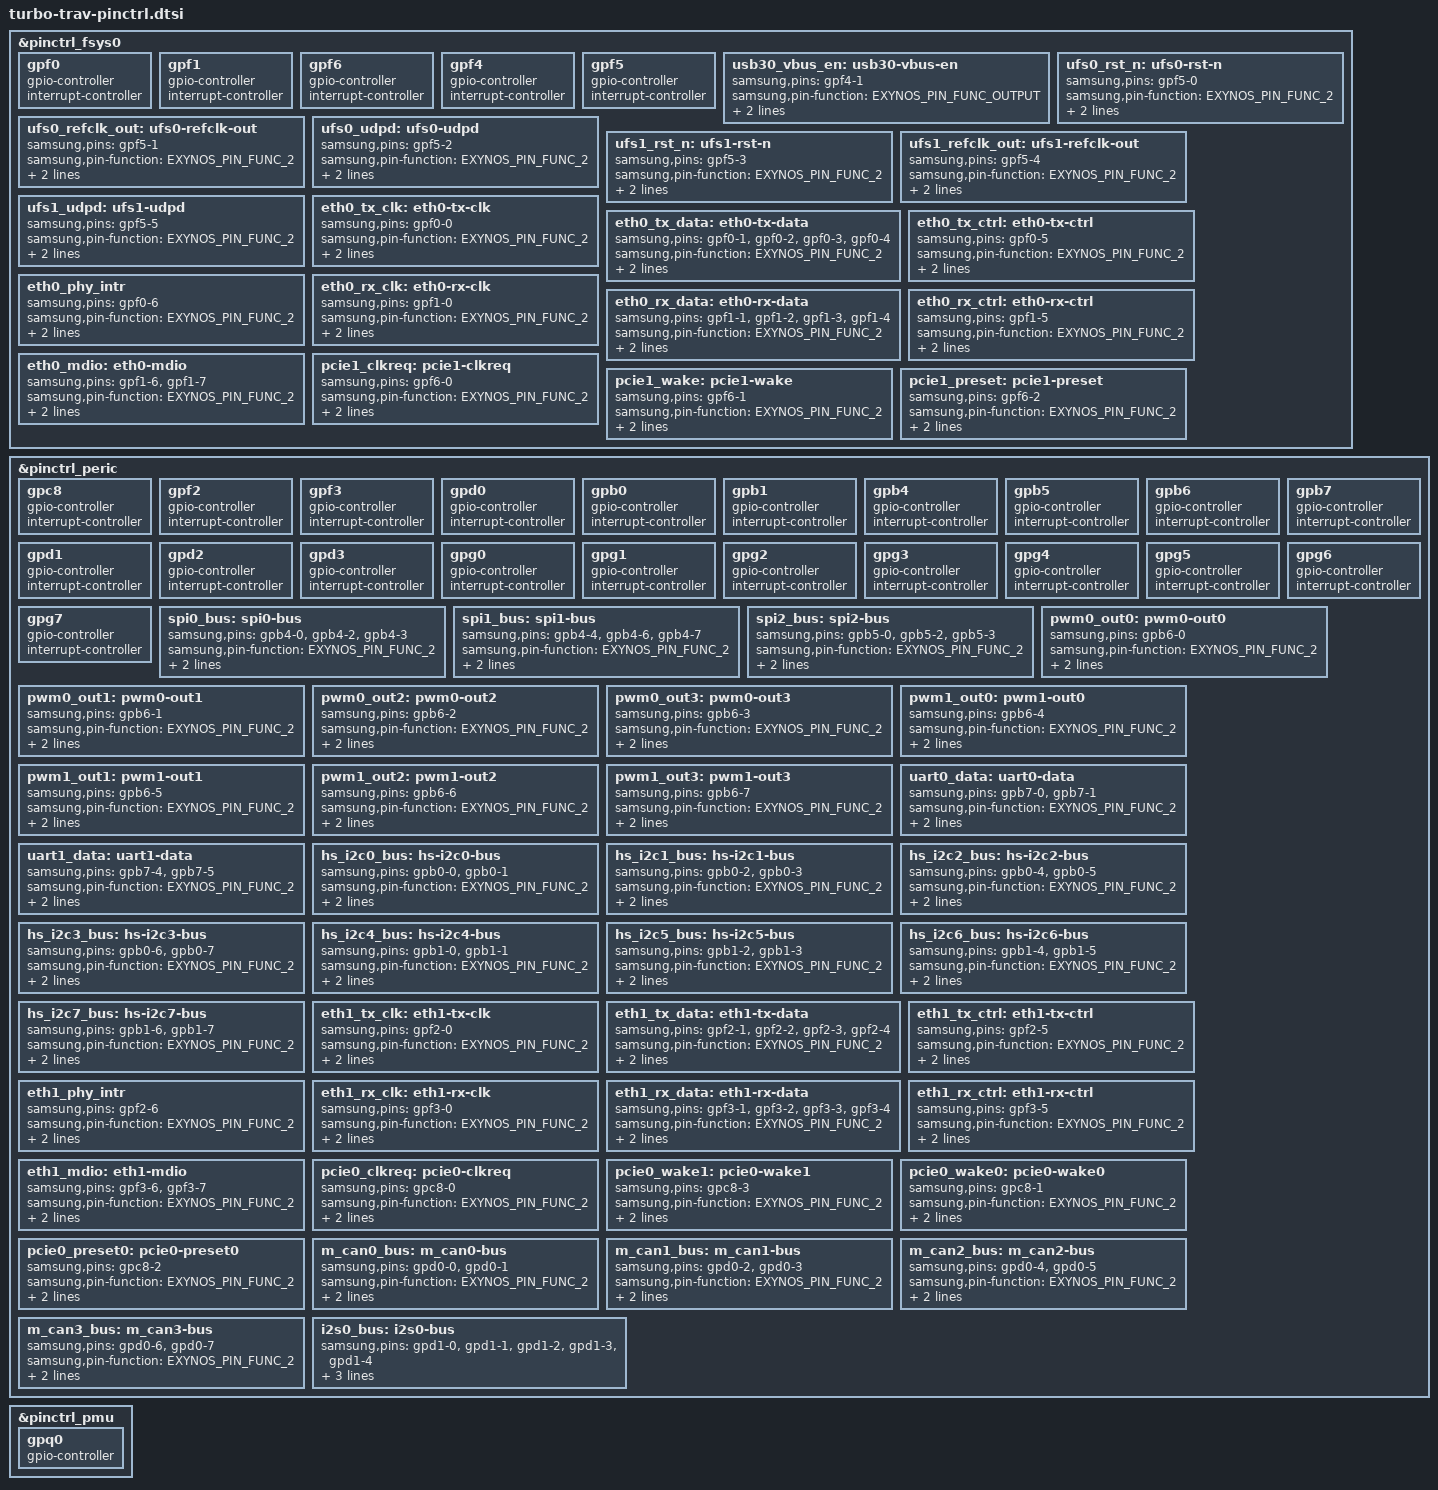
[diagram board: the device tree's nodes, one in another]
/*
 * Samsung's TRAV SoC pin-mux and pin-config device tree source
 *
 * Copyright (c) 2017 Samsung Electronics Co., Ltd.
 *		http://www.samsung.com
 *
 * Samsung's TRAV SoC pin-mux and pin-config options are listed as device
 * tree nodes are listed in this file.
 *
 * This program is free software; you can redistribute it and/or modify
 * it under the terms of the GNU General Public License version 2 as
 * published by the Free Software Foundation.
 */

#include <dt-bindings/pinctrl/samsung.h>

&pinctrl_fsys0 {

	gpf0 {
		gpio-controller;
		#gpio-cells = <2>;

		interrupt-controller;
		#interrupt-cells = <2>;
	};

	gpf1 {
		gpio-controller;
		#gpio-cells = <2>;

		interrupt-controller;
		#interrupt-cells = <2>;
	};

	gpf6: gpf6 {
		gpio-controller;
		#gpio-cells = <2>;

		interrupt-controller;
		#interrupt-cells = <2>;
	};

	gpf4: gpf4 {
		gpio-controller;
		#gpio-cells = <2>;

		interrupt-controller;
		#interrupt-cells = <2>;
	};

	gpf5 {
		gpio-controller;
		#gpio-cells = <2>;

		interrupt-controller;
		#interrupt-cells = <2>;
	};

	usb30_vbus_en: usb30-vbus-en {
		samsung,pins = "gpf4-1";
		samsung,pin-function = <EXYNOS_PIN_FUNC_OUTPUT>;
		samsung,pin-pud = <EXYNOS_PIN_PULL_NONE>;
		samsung,pin-drv = <EXYNOS4_PIN_DRV_LV2>;
	};

	ufs0_rst_n: ufs0-rst-n {
		samsung,pins = "gpf5-0";
		samsung,pin-function = <EXYNOS_PIN_FUNC_2>;
		samsung,pin-pud = <EXYNOS_PIN_PULL_NONE>;
		samsung,pin-drv = <EXYNOS4_PIN_DRV_LV2>;
	};

	ufs0_refclk_out: ufs0-refclk-out {
		samsung,pins = "gpf5-1";
		samsung,pin-function = <EXYNOS_PIN_FUNC_2>;
		samsung,pin-pud = <EXYNOS_PIN_PULL_NONE>;
		samsung,pin-drv = <EXYNOS4_PIN_DRV_LV2>;
	};

	ufs0_udpd: ufs0-udpd {
		samsung,pins = "gpf5-2";
		samsung,pin-function = <EXYNOS_PIN_FUNC_2>;
		samsung,pin-pud = <EXYNOS_PIN_PULL_NONE>;
		samsung,pin-drv = <EXYNOS4_PIN_DRV_LV2>;
	};

	ufs1_rst_n: ufs1-rst-n {
		samsung,pins = "gpf5-3";
		samsung,pin-function = <EXYNOS_PIN_FUNC_2>;
		samsung,pin-pud = <EXYNOS_PIN_PULL_NONE>;
		samsung,pin-drv = <EXYNOS4_PIN_DRV_LV2>;
	};

	ufs1_refclk_out: ufs1-refclk-out {
		samsung,pins = "gpf5-4";
		samsung,pin-function = <EXYNOS_PIN_FUNC_2>;
		samsung,pin-pud = <EXYNOS_PIN_PULL_NONE>;
		samsung,pin-drv = <EXYNOS4_PIN_DRV_LV2>;
	};

	ufs1_udpd: ufs1-udpd {
		samsung,pins = "gpf5-5";
		samsung,pin-function = <EXYNOS_PIN_FUNC_2>;
		samsung,pin-pud = <EXYNOS_PIN_PULL_NONE>;
		samsung,pin-drv = <EXYNOS4_PIN_DRV_LV2>;
	};

	eth0_tx_clk: eth0-tx-clk {
		samsung,pins = "gpf0-0";
		samsung,pin-function = <EXYNOS_PIN_FUNC_2>;
		samsung,pin-pud = <EXYNOS_PIN_PULL_DOWN>;
		samsung,pin-drv = <EXYNOS4_PIN_DRV_LV4>;
	};

	eth0_tx_data: eth0-tx-data {
		samsung,pins = "gpf0-1", "gpf0-2", "gpf0-3", "gpf0-4";
		samsung,pin-function = <EXYNOS_PIN_FUNC_2>;
		samsung,pin-pud = <EXYNOS_PIN_PULL_UP>;
		samsung,pin-drv = <EXYNOS4_PIN_DRV_LV4>;
	};

	eth0_tx_ctrl: eth0-tx-ctrl {
		samsung,pins = "gpf0-5";
		samsung,pin-function = <EXYNOS_PIN_FUNC_2>;
		samsung,pin-pud = <EXYNOS_PIN_PULL_UP>;
		samsung,pin-drv = <EXYNOS4_PIN_DRV_LV4>;
	};

	eth0_phy_intr: eth0_phy_intr {
		samsung,pins = "gpf0-6";
		samsung,pin-function = <EXYNOS_PIN_FUNC_2>;
		samsung,pin-pud = <EXYNOS_PIN_PULL_NONE>;
		samsung,pin-drv = <EXYNOS4_PIN_DRV_LV2>;
	};

	eth0_rx_clk: eth0-rx-clk {
		samsung,pins = "gpf1-0";
		samsung,pin-function = <EXYNOS_PIN_FUNC_2>;
		samsung,pin-pud = <EXYNOS_PIN_PULL_UP>;
		samsung,pin-drv = <EXYNOS4_PIN_DRV_LV4>;
	};

	eth0_rx_data: eth0-rx-data {
		samsung,pins = "gpf1-1", "gpf1-2", "gpf1-3", "gpf1-4";
		samsung,pin-function = <EXYNOS_PIN_FUNC_2>;
		samsung,pin-pud = <EXYNOS_PIN_PULL_UP>;
		samsung,pin-drv = <EXYNOS4_PIN_DRV_LV4>;
	};

	eth0_rx_ctrl: eth0-rx-ctrl {
		samsung,pins = "gpf1-5";
		samsung,pin-function = <EXYNOS_PIN_FUNC_2>;
		samsung,pin-pud = <EXYNOS_PIN_PULL_UP>;
		samsung,pin-drv = <EXYNOS4_PIN_DRV_LV4>;
	};

	eth0_mdio: eth0-mdio {
		samsung,pins = "gpf1-6", "gpf1-7";
		samsung,pin-function = <EXYNOS_PIN_FUNC_2>;
		samsung,pin-pud = <EXYNOS_PIN_PULL_NONE>;
		samsung,pin-drv = <EXYNOS4_PIN_DRV_LV2>;
	};

	pcie1_clkreq: pcie1-clkreq {
		samsung,pins = "gpf6-0";
		samsung,pin-function = <EXYNOS_PIN_FUNC_2>;
		samsung,pin-pud = <EXYNOS_PIN_PULL_UP>;
		samsung,pin-drv = <EXYNOS4_PIN_DRV_LV2>;
	};

	pcie1_wake: pcie1-wake {
		samsung,pins = "gpf6-1";
		samsung,pin-function = <EXYNOS_PIN_FUNC_2>;
		samsung,pin-pud = <EXYNOS_PIN_PULL_UP>;
		samsung,pin-drv = <EXYNOS4_PIN_DRV_LV2>;
	};

	pcie1_preset: pcie1-preset {
		samsung,pins = "gpf6-2";
		samsung,pin-function = <EXYNOS_PIN_FUNC_2>;
		samsung,pin-pud = <EXYNOS_PIN_PULL_UP>;
		samsung,pin-drv = <EXYNOS4_PIN_DRV_LV2>;
	};
};

&pinctrl_peric {

	gpc8: gpc8 {
		gpio-controller;
		#gpio-cells = <2>;

		interrupt-controller;
		#interrupt-cells = <2>;
	};

	gpf2: gpf2 {
		gpio-controller;
		#gpio-cells = <2>;

		interrupt-controller;
		#interrupt-cells = <2>;
	};

	gpf3: gpf3 {
		gpio-controller;
		#gpio-cells = <2>;

		interrupt-controller;
		#interrupt-cells = <2>;
	};

	gpd0: gpd0 {
		gpio-controller;
		#gpio-cells = <2>;

		interrupt-controller;
		#interrupt-cells = <2>;
	};

	gpb0: gpb0 {
		gpio-controller;
		#gpio-cells = <2>;

		interrupt-controller;
		#interrupt-cells = <2>;
	};

	gpb1: gpb1 {
		gpio-controller;
		#gpio-cells = <2>;

		interrupt-controller;
		#interrupt-cells = <2>;
	};

	gpb4: gpb4 {
		gpio-controller;
		#gpio-cells = <2>;

		interrupt-controller;
		#interrupt-cells = <2>;
	};

	gpb5: gpb5 {
		gpio-controller;
		#gpio-cells = <2>;

		interrupt-controller;
		#interrupt-cells = <2>;
	};

	gpb6: gpb6 {
		gpio-controller;
		#gpio-cells = <2>;

		interrupt-controller;
		#interrupt-cells = <2>;
	};

	gpb7: gpb7 {
		gpio-controller;
		#gpio-cells = <2>;

		interrupt-controller;
		#interrupt-cells = <2>;
	};

	gpd1: gpd1 {
		gpio-controller;
		#gpio-cells = <2>;

		interrupt-controller;
		#interrupt-cells = <2>;
	};

	gpd2: gpd2 {
		gpio-controller;
		#gpio-cells = <2>;

		interrupt-controller;
		#interrupt-cells = <2>;
	};

	gpd3: gpd3 {
		gpio-controller;
		#gpio-cells = <2>;

		interrupt-controller;
		#interrupt-cells = <2>;
	};

	gpg0: gpg0 {
		gpio-controller;
		#gpio-cells = <2>;

		interrupt-controller;
		#interrupt-cells = <2>;
	};

	gpg1: gpg1 {
		gpio-controller;
		#gpio-cells = <2>;

		interrupt-controller;
		#interrupt-cells = <2>;
	};

	gpg2: gpg2 {
		gpio-controller;
		#gpio-cells = <2>;

		interrupt-controller;
		#interrupt-cells = <2>;
	};

	gpg3: gpg3 {
		gpio-controller;
		#gpio-cells = <2>;

		interrupt-controller;
		#interrupt-cells = <2>;
	};

	gpg4: gpg4 {
		gpio-controller;
		#gpio-cells = <2>;

		interrupt-controller;
		#interrupt-cells = <2>;
	};

	gpg5: gpg5 {
		gpio-controller;
		#gpio-cells = <2>;

		interrupt-controller;
		#interrupt-cells = <2>;
	};

	gpg6: gpg6 {
		gpio-controller;
		#gpio-cells = <2>;

		interrupt-controller;
		#interrupt-cells = <2>;
	};

	gpg7: gpg7 {
		gpio-controller;
		#gpio-cells = <2>;

		interrupt-controller;
		#interrupt-cells = <2>;
	};

	spi0_bus: spi0-bus {
		samsung,pins = "gpb4-0", "gpb4-2", "gpb4-3";
		samsung,pin-function = <EXYNOS_PIN_FUNC_2>;
		samsung,pin-pud = <EXYNOS_PIN_PULL_UP>;
		samsung,pin-drv = <EXYNOS4_PIN_DRV_LV1>;
	};

	spi1_bus: spi1-bus {
		samsung,pins = "gpb4-4", "gpb4-6", "gpb4-7";
		samsung,pin-function = <EXYNOS_PIN_FUNC_2>;
		samsung,pin-pud = <EXYNOS_PIN_PULL_UP>;
		samsung,pin-drv = <EXYNOS4_PIN_DRV_LV1>;
	};

	spi2_bus: spi2-bus {
		samsung,pins = "gpb5-0", "gpb5-2", "gpb5-3";
		samsung,pin-function = <EXYNOS_PIN_FUNC_2>;
		samsung,pin-pud = <EXYNOS_PIN_PULL_UP>;
		samsung,pin-drv = <EXYNOS4_PIN_DRV_LV1>;
	};
	
	pwm0_out0: pwm0-out0 {
		samsung,pins = "gpb6-0";
		samsung,pin-function = <EXYNOS_PIN_FUNC_2>;
		samsung,pin-pud = <EXYNOS_PIN_PULL_UP>;
		samsung,pin-drv = <EXYNOS4_PIN_DRV_LV2>;
	};

	pwm0_out1: pwm0-out1 {
		samsung,pins = "gpb6-1";
		samsung,pin-function = <EXYNOS_PIN_FUNC_2>;
		samsung,pin-pud = <EXYNOS_PIN_PULL_UP>;
		samsung,pin-drv = <EXYNOS4_PIN_DRV_LV2>;
	};

	pwm0_out2: pwm0-out2 {
		samsung,pins = "gpb6-2";
		samsung,pin-function = <EXYNOS_PIN_FUNC_2>;
		samsung,pin-pud = <EXYNOS_PIN_PULL_UP>;
		samsung,pin-drv = <EXYNOS4_PIN_DRV_LV2>;
	};

	pwm0_out3: pwm0-out3 {
		samsung,pins = "gpb6-3";
		samsung,pin-function = <EXYNOS_PIN_FUNC_2>;
		samsung,pin-pud = <EXYNOS_PIN_PULL_UP>;
		samsung,pin-drv = <EXYNOS4_PIN_DRV_LV2>;
	};

	pwm1_out0: pwm1-out0 {
		samsung,pins = "gpb6-4";
		samsung,pin-function = <EXYNOS_PIN_FUNC_2>;
		samsung,pin-pud = <EXYNOS_PIN_PULL_UP>;
		samsung,pin-drv = <EXYNOS4_PIN_DRV_LV2>;
	};

	pwm1_out1: pwm1-out1 {
		samsung,pins = "gpb6-5";
		samsung,pin-function = <EXYNOS_PIN_FUNC_2>;
		samsung,pin-pud = <EXYNOS_PIN_PULL_UP>;
		samsung,pin-drv = <EXYNOS4_PIN_DRV_LV2>;
	};

	pwm1_out2: pwm1-out2 {
		samsung,pins = "gpb6-6";
		samsung,pin-function = <EXYNOS_PIN_FUNC_2>;
		samsung,pin-pud = <EXYNOS_PIN_PULL_UP>;
		samsung,pin-drv = <EXYNOS4_PIN_DRV_LV2>;
	};

	pwm1_out3: pwm1-out3 {
		samsung,pins = "gpb6-7";
		samsung,pin-function = <EXYNOS_PIN_FUNC_2>;
		samsung,pin-pud = <EXYNOS_PIN_PULL_UP>;
		samsung,pin-drv = <EXYNOS4_PIN_DRV_LV2>;
	};

	uart0_data: uart0-data {
		samsung,pins = "gpb7-0", "gpb7-1";
		samsung,pin-function = <EXYNOS_PIN_FUNC_2>;
		samsung,pin-pud = <EXYNOS_PIN_PULL_NONE>;
		samsung,pin-drv = <EXYNOS4_PIN_DRV_LV1>;
	};

	uart1_data: uart1-data {
		samsung,pins = "gpb7-4", "gpb7-5";
		samsung,pin-function = <EXYNOS_PIN_FUNC_2>;
		samsung,pin-pud = <EXYNOS_PIN_PULL_NONE>;
		samsung,pin-drv = <EXYNOS4_PIN_DRV_LV1>;
	};

	hs_i2c0_bus: hs-i2c0-bus {
		samsung,pins = "gpb0-0", "gpb0-1";
		samsung,pin-function = <EXYNOS_PIN_FUNC_2>;
		samsung,pin-pud = <EXYNOS_PIN_PULL_UP>;
		samsung,pin-drv = <EXYNOS4_PIN_DRV_LV1>;
	};

	hs_i2c1_bus: hs-i2c1-bus {
		samsung,pins = "gpb0-2", "gpb0-3";
		samsung,pin-function = <EXYNOS_PIN_FUNC_2>;
		samsung,pin-pud = <EXYNOS_PIN_PULL_UP>;
		samsung,pin-drv = <EXYNOS4_PIN_DRV_LV1>;
	};

	hs_i2c2_bus: hs-i2c2-bus {
		samsung,pins = "gpb0-4", "gpb0-5";
		samsung,pin-function = <EXYNOS_PIN_FUNC_2>;
		samsung,pin-pud = <EXYNOS_PIN_PULL_UP>;
		samsung,pin-drv = <EXYNOS4_PIN_DRV_LV1>;
	};

	hs_i2c3_bus: hs-i2c3-bus {
		samsung,pins = "gpb0-6", "gpb0-7";
		samsung,pin-function = <EXYNOS_PIN_FUNC_2>;
		samsung,pin-pud = <EXYNOS_PIN_PULL_UP>;
		samsung,pin-drv = <EXYNOS4_PIN_DRV_LV1>;
	};

	hs_i2c4_bus: hs-i2c4-bus {
		samsung,pins = "gpb1-0", "gpb1-1";
		samsung,pin-function = <EXYNOS_PIN_FUNC_2>;
		samsung,pin-pud = <EXYNOS_PIN_PULL_UP>;
		samsung,pin-drv = <EXYNOS4_PIN_DRV_LV1>;
	};

	hs_i2c5_bus: hs-i2c5-bus {
		samsung,pins = "gpb1-2", "gpb1-3";
		samsung,pin-function = <EXYNOS_PIN_FUNC_2>;
		samsung,pin-pud = <EXYNOS_PIN_PULL_UP>;
		samsung,pin-drv = <EXYNOS4_PIN_DRV_LV1>;
	};

	hs_i2c6_bus: hs-i2c6-bus {
		samsung,pins = "gpb1-4", "gpb1-5";
		samsung,pin-function = <EXYNOS_PIN_FUNC_2>;
		samsung,pin-pud = <EXYNOS_PIN_PULL_UP>;
		samsung,pin-drv = <EXYNOS4_PIN_DRV_LV1>;
	};

	hs_i2c7_bus: hs-i2c7-bus {
		samsung,pins = "gpb1-6", "gpb1-7";
		samsung,pin-function = <EXYNOS_PIN_FUNC_2>;
		samsung,pin-pud = <EXYNOS_PIN_PULL_UP>;
		samsung,pin-drv = <EXYNOS4_PIN_DRV_LV1>;
	};

	eth1_tx_clk: eth1-tx-clk {
		samsung,pins = "gpf2-0";
		samsung,pin-function = <EXYNOS_PIN_FUNC_2>;
		samsung,pin-pud = <EXYNOS_PIN_PULL_DOWN>;
		samsung,pin-drv = <EXYNOS4_PIN_DRV_LV4>;
	};

	eth1_tx_data: eth1-tx-data {
		samsung,pins = "gpf2-1", "gpf2-2", "gpf2-3", "gpf2-4";
		samsung,pin-function = <EXYNOS_PIN_FUNC_2>;
		samsung,pin-pud = <EXYNOS_PIN_PULL_UP>;
		samsung,pin-drv = <EXYNOS4_PIN_DRV_LV4>;
	};

	eth1_tx_ctrl: eth1-tx-ctrl {
		samsung,pins = "gpf2-5";
		samsung,pin-function = <EXYNOS_PIN_FUNC_2>;
		samsung,pin-pud = <EXYNOS_PIN_PULL_UP>;
		samsung,pin-drv = <EXYNOS4_PIN_DRV_LV4>;
	};

	eth1_phy_intr: eth1_phy_intr {
		samsung,pins = "gpf2-6";
		samsung,pin-function = <EXYNOS_PIN_FUNC_2>;
		samsung,pin-pud = <EXYNOS_PIN_PULL_UP>;
		samsung,pin-drv = <EXYNOS4_PIN_DRV_LV2>;
	};

	eth1_rx_clk: eth1-rx-clk {
		samsung,pins = "gpf3-0";
		samsung,pin-function = <EXYNOS_PIN_FUNC_2>;
		samsung,pin-pud = <EXYNOS_PIN_PULL_UP>;
		samsung,pin-drv = <EXYNOS4_PIN_DRV_LV4>;
	};

	eth1_rx_data: eth1-rx-data {
		samsung,pins = "gpf3-1", "gpf3-2", "gpf3-3", "gpf3-4";
		samsung,pin-function = <EXYNOS_PIN_FUNC_2>;
		samsung,pin-pud = <EXYNOS_PIN_PULL_UP>;
		samsung,pin-drv = <EXYNOS4_PIN_DRV_LV4>;
	};

	eth1_rx_ctrl: eth1-rx-ctrl {
		samsung,pins = "gpf3-5";
		samsung,pin-function = <EXYNOS_PIN_FUNC_2>;
		samsung,pin-pud = <EXYNOS_PIN_PULL_UP>;
		samsung,pin-drv = <EXYNOS4_PIN_DRV_LV4>;
	};

	eth1_mdio: eth1-mdio {
		samsung,pins = "gpf3-6", "gpf3-7";
		samsung,pin-function = <EXYNOS_PIN_FUNC_2>;
		samsung,pin-pud = <EXYNOS_PIN_PULL_UP>;
		samsung,pin-drv = <EXYNOS4_PIN_DRV_LV2>;
	};

	pcie0_clkreq: pcie0-clkreq {
		samsung,pins = "gpc8-0";
		samsung,pin-function = <EXYNOS_PIN_FUNC_2>;
		samsung,pin-pud = <EXYNOS_PIN_PULL_UP>;
		samsung,pin-drv = <EXYNOS4_PIN_DRV_LV2>;
	};

	pcie0_wake1: pcie0-wake1 {
		samsung,pins = "gpc8-3";
		samsung,pin-function = <EXYNOS_PIN_FUNC_2>;
		samsung,pin-pud = <EXYNOS_PIN_PULL_UP>;
		samsung,pin-drv = <EXYNOS4_PIN_DRV_LV2>;
	};

	pcie0_wake0: pcie0-wake0 {
		samsung,pins = "gpc8-1";
		samsung,pin-function = <EXYNOS_PIN_FUNC_2>;
		samsung,pin-pud = <EXYNOS_PIN_PULL_UP>;
		samsung,pin-drv = <EXYNOS4_PIN_DRV_LV2>;
	};

	pcie0_preset0: pcie0-preset0 {
		samsung,pins = "gpc8-2";
		samsung,pin-function = <EXYNOS_PIN_FUNC_2>;
		samsung,pin-pud = <EXYNOS_PIN_PULL_UP>;
		samsung,pin-drv = <EXYNOS4_PIN_DRV_LV2>;
	};

	m_can0_bus: m_can0-bus {
		samsung,pins = "gpd0-0", "gpd0-1";
		samsung,pin-function = <EXYNOS_PIN_FUNC_2>;
		samsung,pin-pud = <EXYNOS_PIN_PULL_UP>;
		samsung,pin-drv = <EXYNOS4_PIN_DRV_LV1>;
	};

	m_can1_bus: m_can1-bus {
		samsung,pins = "gpd0-2", "gpd0-3";
		samsung,pin-function = <EXYNOS_PIN_FUNC_2>;
		samsung,pin-pud = <EXYNOS_PIN_PULL_UP>;
		samsung,pin-drv = <EXYNOS4_PIN_DRV_LV1>;
	};

	m_can2_bus: m_can2-bus {
		samsung,pins = "gpd0-4", "gpd0-5";
		samsung,pin-function = <EXYNOS_PIN_FUNC_2>;
		samsung,pin-pud = <EXYNOS_PIN_PULL_UP>;
		samsung,pin-drv = <EXYNOS4_PIN_DRV_LV1>;
	};

	m_can3_bus: m_can3-bus {
		samsung,pins = "gpd0-6", "gpd0-7";
		samsung,pin-function = <EXYNOS_PIN_FUNC_2>;
		samsung,pin-pud = <EXYNOS_PIN_PULL_UP>;
		samsung,pin-drv = <EXYNOS4_PIN_DRV_LV1>;
	};

	i2s0_bus: i2s0-bus {
		samsung,pins = "gpd1-0", "gpd1-1", "gpd1-2", "gpd1-3", "gpd1-4";
		samsung,pin-function = <EXYNOS_PIN_FUNC_2>;
		samsung,pin-pud = <EXYNOS_PIN_PULL_DOWN>;
		samsung,pin-drv = <EXYNOS4_PIN_DRV_LV1>;
	};
};

&pinctrl_pmu {

	gpq0: gpq0 {
		gpio-controller;
		#gpio-cells = <2>;
	};
};
